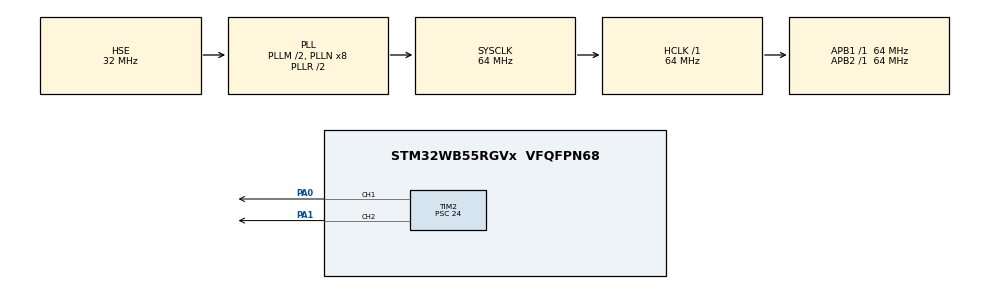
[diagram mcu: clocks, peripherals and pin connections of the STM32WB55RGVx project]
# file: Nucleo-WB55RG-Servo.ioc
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Mcu.Family=STM32WB
Mcu.Name=STM32WB55RGVx
Mcu.Package=VFQFPN68
NVIC.PriorityGroup=NVIC_PRIORITYGROUP_4
OSC_IN.Mode=HSE-External-Clock-Source
OSC_IN.Signal=RCC_OSC_IN
PA0.Signal=S_TIM2_CH1
PA1.Signal=S_TIM2_CH2
PA13.Mode=Serial_Wire
PA13.Signal=SYS_JTMS-SWDIO
PA14.Mode=Serial_Wire
PA14.Signal=SYS_JTCK-SWCLK
ProjectManager.HeapSize=0x200
ProjectManager.StackSize=0x400
ProjectManager.TargetToolchain=STM32CubeIDE
RCC.ADCFreq_Value=64000000
RCC.AHB2CLKDivider=RCC_SYSCLK_DIV2
RCC.AHBFreq_Value=64000000
RCC.APB1Freq_Value=64000000
RCC.APB1TimFreq_Value=64000000
RCC.APB2Freq_Value=64000000
RCC.APB2TimFreq_Value=64000000
RCC.APB3Freq_Value=16000000
RCC.Cortex2_Div=SYSTICK_CLKSOURCE_HCLK_DIV8
RCC.CortexFreq_Value=64000000
RCC.HCLKFreq_Value=64000000
RCC.HSE_VALUE=32000000
RCC.HSI48_VALUE=48000000
RCC.HSI_VALUE=16000000
RCC.LSE_VALUE=32768
RCC.PLLM=RCC_PLLM_DIV2
RCC.PLLSourceVirtual=RCC_PLLSOURCE_HSE
RCC.SYSCLKFreq_VALUE=64000000
RCC.SYSCLKSource=RCC_SYSCLKSOURCE_PLLCLK
RCC.USBFreq_Value=64000000
RCC.VCOOutputFreq_Value=128000000
SH.S_TIM2_CH1.0=TIM2_CH1,PWM Generation1 CH1
SH.S_TIM2_CH2.0=TIM2_CH2,PWM Generation2 CH2
TIM2.Channel-PWM\ Generation1\ CH1=TIM_CHANNEL_1
TIM2.Channel-PWM\ Generation2\ CH2=TIM_CHANNEL_2
TIM2.Period=57599
TIM2.Prescaler=24
TIM2.Pulse-PWM\ Generation1\ CH1=3839
TIM2.Pulse-PWM\ Generation2\ CH2=3839
VP_TIM2_VS_ClockSourceINT.Mode=Internal
board=custom

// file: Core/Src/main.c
/* USER CODE BEGIN Header */
/**
  ******************************************************************************
  * @file           : main.c
  * @brief          : Main program body
  ******************************************************************************
  * @attention
  *
  * Copyright (c) 2023 STMicroelectronics.
  * All rights reserved.
  *
  * This software is licensed under terms that can be found in the LICENSE file
  * in the root directory of this software component.
  * If no LICENSE file comes with this software, it is provided AS-IS.
  *
  ******************************************************************************
  */
/* USER CODE END Header */
#include "main.h"

TIM_HandleTypeDef htim2;

void SystemClock_Config(void);
void PeriphCommonClock_Config(void);
static void MX_GPIO_Init(void);
static void MX_TIM2_Init(void);

int main(void)
{
  /* USER CODE BEGIN 1 */
	uint16_t data = 0;
  /* USER CODE END 1 */

  /* MCU Configuration--------------------------------------------------------*/

  /* Reset of all peripherals, Initializes the Flash interface and the Systick. */
  HAL_Init();

  /* Configure the system clock */
  SystemClock_Config();

/* Configure the peripherals common clocks */
  PeriphCommonClock_Config();

  /* Initialize all configured peripherals */
  MX_GPIO_Init();
  MX_TIM2_Init();
  /* USER CODE BEGIN 2 */

  HAL_TIM_PWM_Start(&htim2, TIM_CHANNEL_1);
  HAL_TIM_PWM_Start(&htim2, TIM_CHANNEL_2);
  __HAL_TIM_SetCompare(&htim2, TIM_CHANNEL_1, 3839);
  __HAL_TIM_SetCompare(&htim2, TIM_CHANNEL_2, 3839);
  HAL_Delay(5000);

#if 1
  // 1.5ms to 2.5ms
  for(uint8_t i = 0; i <= 255; i++)
  {
    data = 3839+ 10*i;
    __HAL_TIM_SetCompare(&htim2, TIM_CHANNEL_1, data);
    __HAL_TIM_SetCompare(&htim2, TIM_CHANNEL_2, data);
    HAL_Delay(100);
  }
#endif

  /* USER CODE END 2 */

  /* Infinite loop */
  while (1)
  {

  }
}

void SystemClock_Config(void)
{
  RCC_OscInitTypeDef RCC_OscInitStruct = {0};
  RCC_ClkInitTypeDef RCC_ClkInitStruct = {0};

  /** Configure the main internal regulator output voltage
  */
  __HAL_PWR_VOLTAGESCALING_CONFIG(PWR_REGULATOR_VOLTAGE_SCALE1);

  /** Initializes the RCC Oscillators according to the specified parameters
  * in the RCC_OscInitTypeDef structure.
  */
  RCC_OscInitStruct.OscillatorType = RCC_OSCILLATORTYPE_HSI|RCC_OSCILLATORTYPE_HSE;
  RCC_OscInitStruct.HSEState = RCC_HSE_ON;
  RCC_OscInitStruct.HSIState = RCC_HSI_ON;
  RCC_OscInitStruct.HSICalibrationValue = RCC_HSICALIBRATION_DEFAULT;
  RCC_OscInitStruct.PLL.PLLState = RCC_PLL_ON;
  RCC_OscInitStruct.PLL.PLLSource = RCC_PLLSOURCE_HSE;
  RCC_OscInitStruct.PLL.PLLM = RCC_PLLM_DIV2;
  RCC_OscInitStruct.PLL.PLLN = 8;
  RCC_OscInitStruct.PLL.PLLP = RCC_PLLP_DIV2;
  RCC_OscInitStruct.PLL.PLLR = RCC_PLLR_DIV2;
  RCC_OscInitStruct.PLL.PLLQ = RCC_PLLQ_DIV2;
  if (HAL_RCC_OscConfig(&RCC_OscInitStruct) != HAL_OK)
  {
    Error_Handler();
  }

  /** Configure the SYSCLKSource, HCLK, PCLK1 and PCLK2 clocks dividers
  */
  RCC_ClkInitStruct.ClockType = RCC_CLOCKTYPE_HCLK4|RCC_CLOCKTYPE_HCLK2
                              |RCC_CLOCKTYPE_HCLK|RCC_CLOCKTYPE_SYSCLK
                              |RCC_CLOCKTYPE_PCLK1|RCC_CLOCKTYPE_PCLK2;
  RCC_ClkInitStruct.SYSCLKSource = RCC_SYSCLKSOURCE_PLLCLK;
  RCC_ClkInitStruct.AHBCLKDivider = RCC_SYSCLK_DIV1;
  RCC_ClkInitStruct.APB1CLKDivider = RCC_HCLK_DIV1;
  RCC_ClkInitStruct.APB2CLKDivider = RCC_HCLK_DIV1;
  RCC_ClkInitStruct.AHBCLK2Divider = RCC_SYSCLK_DIV2;
  RCC_ClkInitStruct.AHBCLK4Divider = RCC_SYSCLK_DIV1;

  if (HAL_RCC_ClockConfig(&RCC_ClkInitStruct, FLASH_LATENCY_3) != HAL_OK)
  {
    Error_Handler();
  }
}

void PeriphCommonClock_Config(void)
{
  RCC_PeriphCLKInitTypeDef PeriphClkInitStruct = {0};

  /** Initializes the peripherals clock
  */
  PeriphClkInitStruct.PeriphClockSelection = RCC_PERIPHCLK_SMPS;
  PeriphClkInitStruct.SmpsClockSelection = RCC_SMPSCLKSOURCE_HSI;
  PeriphClkInitStruct.SmpsDivSelection = RCC_SMPSCLKDIV_RANGE1;

  if (HAL_RCCEx_PeriphCLKConfig(&PeriphClkInitStruct) != HAL_OK)
  {
    Error_Handler();
  }
}

static void MX_TIM2_Init(void)
{

  TIM_ClockConfigTypeDef sClockSourceConfig = {0};
  TIM_MasterConfigTypeDef sMasterConfig = {0};
  TIM_OC_InitTypeDef sConfigOC = {0};

  htim2.Instance = TIM2;
  htim2.Init.Prescaler = 24;
  htim2.Init.CounterMode = TIM_COUNTERMODE_UP;
  htim2.Init.Period = 57599;
  htim2.Init.ClockDivision = TIM_CLOCKDIVISION_DIV1;
  htim2.Init.AutoReloadPreload = TIM_AUTORELOAD_PRELOAD_DISABLE;
  if (HAL_TIM_Base_Init(&htim2) != HAL_OK)
  {
    Error_Handler();
  }
  sClockSourceConfig.ClockSource = TIM_CLOCKSOURCE_INTERNAL;
  if (HAL_TIM_ConfigClockSource(&htim2, &sClockSourceConfig) != HAL_OK)
  {
    Error_Handler();
  }
  if (HAL_TIM_PWM_Init(&htim2) != HAL_OK)
  {
    Error_Handler();
  }
  sMasterConfig.MasterOutputTrigger = TIM_TRGO_RESET;
  sMasterConfig.MasterSlaveMode = TIM_MASTERSLAVEMODE_DISABLE;
  if (HAL_TIMEx_MasterConfigSynchronization(&htim2, &sMasterConfig) != HAL_OK)
  {
    Error_Handler();
  }
  sConfigOC.OCMode = TIM_OCMODE_PWM1;
  sConfigOC.Pulse = 3839;
  sConfigOC.OCPolarity = TIM_OCPOLARITY_HIGH;
  sConfigOC.OCFastMode = TIM_OCFAST_DISABLE;
  if (HAL_TIM_PWM_ConfigChannel(&htim2, &sConfigOC, TIM_CHANNEL_1) != HAL_OK)
  {
    Error_Handler();
  }
  if (HAL_TIM_PWM_ConfigChannel(&htim2, &sConfigOC, TIM_CHANNEL_2) != HAL_OK)
  {
    Error_Handler();
  }
  HAL_TIM_MspPostInit(&htim2);

}

static void MX_GPIO_Init(void)
{

  /* GPIO Ports Clock Enable */
  __HAL_RCC_GPIOA_CLK_ENABLE();

}

void Error_Handler(void)
{
  __disable_irq();
  while (1)
  {
  }
}
